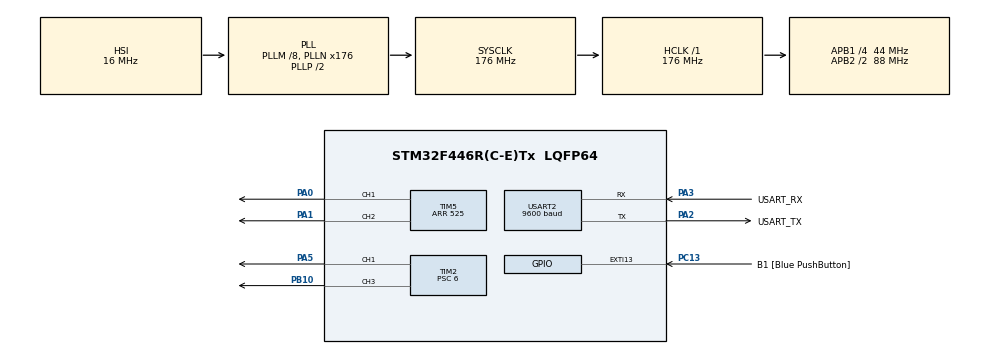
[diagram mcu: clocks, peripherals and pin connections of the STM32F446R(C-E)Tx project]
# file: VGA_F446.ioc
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Mcu.Family=STM32F4
Mcu.Name=STM32F446R(C-E)Tx
Mcu.Package=LQFP64
NVIC.PriorityGroup=NVIC_PRIORITYGROUP_0
NVIC.TIM2_IRQn=true\:0\:0\:false\:false\:true\:true\:true\:true
PA0-WKUP.Signal=S_TIM5_CH1
PA1.Signal=S_TIM5_CH2
PA13.GPIO_Label=TMS
PA13.Mode=Serial_Wire
PA13.Signal=SYS_JTMS-SWDIO
PA14.GPIO_Label=TCK
PA14.Mode=Serial_Wire
PA14.Signal=SYS_JTCK-SWCLK
PA2.GPIO_Label=USART_TX
PA2.Mode=Asynchronous
PA2.Signal=USART2_TX
PA3.GPIO_Label=USART_RX
PA3.Mode=Asynchronous
PA3.Signal=USART2_RX
PA5.Signal=S_TIM2_CH1_ETR
PB10.Signal=S_TIM2_CH3
PB3.GPIO_Label=SWO
PB3.Signal=SYS_JTDO-SWO
PC13.GPIO_Label=B1 [Blue PushButton]
PC13.GPIO_ModeDefaultEXTI=GPIO_MODE_IT_FALLING
PC13.Signal=GPXTI13
PC14-OSC32_IN.Mode=LSE-External-Oscillator
PC14-OSC32_IN.Signal=RCC_OSC32_IN
PC15-OSC32_OUT.Mode=LSE-External-Oscillator
PC15-OSC32_OUT.Signal=RCC_OSC32_OUT
PH0-OSC_IN.Mode=HSE-External-Oscillator
PH0-OSC_IN.Signal=RCC_OSC_IN
PH1-OSC_OUT.Mode=HSE-External-Oscillator
PH1-OSC_OUT.Signal=RCC_OSC_OUT
ProjectManager.HeapSize=0x200
ProjectManager.StackSize=0x400
ProjectManager.TargetToolchain=STM32CubeIDE
RCC.48MHZClocksFreq_Value=84000000
RCC.AHBFreq_Value=176000000
RCC.APB1CLKDivider=RCC_HCLK_DIV4
RCC.APB1Freq_Value=44000000
RCC.APB1TimFreq_Value=88000000
RCC.APB2CLKDivider=RCC_HCLK_DIV2
RCC.APB2Freq_Value=88000000
RCC.APB2TimFreq_Value=176000000
RCC.CortexFreq_Value=176000000
RCC.FLatency-AdvancedSettings=FLASH_LATENCY_5
RCC.HCLKFreq_Value=176000000
RCC.HSE_VALUE=8000000
RCC.HSI_VALUE=16000000
RCC.PLLM=8
RCC.PLLN=176
RCC.SYSCLKFreq_VALUE=176000000
RCC.SYSCLKSource=RCC_SYSCLKSOURCE_PLLCLK
RCC.USBFreq_Value=176000000
RCC.VCOOutputFreq_Value=352000000
SH.S_TIM2_CH1_ETR.0=TIM2_CH1,Output Compare1 CH1
SH.S_TIM2_CH3.0=TIM2_CH3,PWM Generation3 CH3
SH.S_TIM5_CH1.0=TIM5_CH1,PWM Generation1 CH1
SH.S_TIM5_CH2.0=TIM5_CH2,Output Compare2 CH2
TIM2.AutoReloadPreload=TIM_AUTORELOAD_PRELOAD_DISABLE
TIM2.Channel-Output\ Compare1\ CH1=TIM_CHANNEL_1
TIM2.Channel-PWM\ Generation3\ CH3=TIM_CHANNEL_3
TIM2.OCMode_1=TIM_OCMODE_TOGGLE
TIM2.Period=800
TIM2.Prescaler=6
TIM2.Pulse-Output\ Compare1\ CH1=144
TIM2.Pulse-PWM\ Generation3\ CH3=96
TIM2.TIM_MasterOutputTrigger=TIM_TRGO_UPDATE
TIM2.TIM_MasterSlaveMode=TIM_MASTERSLAVEMODE_DISABLE
TIM5.Channel-Output\ Compare2\ CH2=TIM_CHANNEL_2
TIM5.Channel-PWM\ Generation1\ CH1=TIM_CHANNEL_1
TIM5.OCMode_2=TIM_OCMODE_TOGGLE
TIM5.OCPolarity_1=TIM_OCPOLARITY_HIGH
TIM5.Period=525
TIM5.Pulse-Output\ Compare2\ CH2=35
TIM5.Pulse-PWM\ Generation1\ CH1=2
USART2.BaudRate=9600
USART2.VirtualMode=VM_ASYNC
VP_TIM2_VS_ClockSourceINT.Mode=Internal
VP_TIM5_VS_ClockSourceITR.Mode=TriggerSource_ITR0
VP_TIM5_VS_ControllerModeClock.Mode=Clock Mode
board=NUCLEO-F446RE

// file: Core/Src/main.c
/* USER CODE BEGIN Header */
/**
  ******************************************************************************
  * @file           : main.c
  * @brief          : Main program body
  ******************************************************************************
  * @attention
  *
  * Copyright (c) 2024 STMicroelectronics.
  * All rights reserved.
  *
  * This software is licensed under terms that can be found in the LICENSE file
  * in the root directory of this software component.
  * If no LICENSE file comes with this software, it is provided AS-IS.
  *
  ******************************************************************************
  */
/* USER CODE END Header */
#include "main.h"

TIM_HandleTypeDef htim2;
TIM_HandleTypeDef htim5;

UART_HandleTypeDef huart2;

void SystemClock_Config(void);
static void MX_GPIO_Init(void);
static void MX_TIM2_Init(void);
static void MX_TIM5_Init(void);
static void MX_USART2_UART_Init(void);

int main(void)
{

  /* MCU Configuration--------------------------------------------------------*/

  /* Reset of all peripherals, Initializes the Flash interface and the Systick. */
  HAL_Init();

  /* Configure the system clock */
  SystemClock_Config();

  /* Initialize all configured peripherals */
  MX_GPIO_Init();
  MX_TIM2_Init();
  MX_TIM5_Init();
  MX_USART2_UART_Init();
  /* USER CODE BEGIN 2 */

  HAL_TIM_Base_Start(&htim2);
  HAL_TIM_OC_Start(&htim2, TIM_CHANNEL_1);
  HAL_TIM_PWM_Start(&htim2, TIM_CHANNEL_3);
  HAL_TIM_Base_Start(&htim5);
  HAL_TIM_PWM_Start(&htim5, TIM_CHANNEL_1);
  HAL_TIM_OC_Start(&htim5, TIM_CHANNEL_2);

  /* USER CODE END 2 */

  /* Infinite loop */
  while (1)
  {

  }
}

void SystemClock_Config(void)
{
  RCC_OscInitTypeDef RCC_OscInitStruct = {0};
  RCC_ClkInitTypeDef RCC_ClkInitStruct = {0};

  /** Configure the main internal regulator output voltage
  */
  __HAL_RCC_PWR_CLK_ENABLE();
  __HAL_PWR_VOLTAGESCALING_CONFIG(PWR_REGULATOR_VOLTAGE_SCALE1);

  /** Initializes the RCC Oscillators according to the specified parameters
  * in the RCC_OscInitTypeDef structure.
  */
  RCC_OscInitStruct.OscillatorType = RCC_OSCILLATORTYPE_HSI;
  RCC_OscInitStruct.HSIState = RCC_HSI_ON;
  RCC_OscInitStruct.HSICalibrationValue = RCC_HSICALIBRATION_DEFAULT;
  RCC_OscInitStruct.PLL.PLLState = RCC_PLL_ON;
  RCC_OscInitStruct.PLL.PLLSource = RCC_PLLSOURCE_HSI;
  RCC_OscInitStruct.PLL.PLLM = 8;
  RCC_OscInitStruct.PLL.PLLN = 176;
  RCC_OscInitStruct.PLL.PLLP = RCC_PLLP_DIV2;
  RCC_OscInitStruct.PLL.PLLQ = 2;
  RCC_OscInitStruct.PLL.PLLR = 2;
  if (HAL_RCC_OscConfig(&RCC_OscInitStruct) != HAL_OK)
  {
    Error_Handler();
  }

  /** Activate the Over-Drive mode
  */
  if (HAL_PWREx_EnableOverDrive() != HAL_OK)
  {
    Error_Handler();
  }

  /** Initializes the CPU, AHB and APB buses clocks
  */
  RCC_ClkInitStruct.ClockType = RCC_CLOCKTYPE_HCLK|RCC_CLOCKTYPE_SYSCLK
                              |RCC_CLOCKTYPE_PCLK1|RCC_CLOCKTYPE_PCLK2;
  RCC_ClkInitStruct.SYSCLKSource = RCC_SYSCLKSOURCE_PLLCLK;
  RCC_ClkInitStruct.AHBCLKDivider = RCC_SYSCLK_DIV1;
  RCC_ClkInitStruct.APB1CLKDivider = RCC_HCLK_DIV4;
  RCC_ClkInitStruct.APB2CLKDivider = RCC_HCLK_DIV2;

  if (HAL_RCC_ClockConfig(&RCC_ClkInitStruct, FLASH_LATENCY_5) != HAL_OK)
  {
    Error_Handler();
  }
}

static void MX_TIM2_Init(void)
{

  TIM_ClockConfigTypeDef sClockSourceConfig = {0};
  TIM_MasterConfigTypeDef sMasterConfig = {0};
  TIM_OC_InitTypeDef sConfigOC = {0};

  htim2.Instance = TIM2;
  htim2.Init.Prescaler = 6;
  htim2.Init.CounterMode = TIM_COUNTERMODE_UP;
  htim2.Init.Period = 800;
  htim2.Init.ClockDivision = TIM_CLOCKDIVISION_DIV1;
  htim2.Init.AutoReloadPreload = TIM_AUTORELOAD_PRELOAD_DISABLE;
  if (HAL_TIM_Base_Init(&htim2) != HAL_OK)
  {
    Error_Handler();
  }
  sClockSourceConfig.ClockSource = TIM_CLOCKSOURCE_INTERNAL;
  if (HAL_TIM_ConfigClockSource(&htim2, &sClockSourceConfig) != HAL_OK)
  {
    Error_Handler();
  }
  if (HAL_TIM_OC_Init(&htim2) != HAL_OK)
  {
    Error_Handler();
  }
  if (HAL_TIM_PWM_Init(&htim2) != HAL_OK)
  {
    Error_Handler();
  }
  sMasterConfig.MasterOutputTrigger = TIM_TRGO_UPDATE;
  sMasterConfig.MasterSlaveMode = TIM_MASTERSLAVEMODE_DISABLE;
  if (HAL_TIMEx_MasterConfigSynchronization(&htim2, &sMasterConfig) != HAL_OK)
  {
    Error_Handler();
  }
  sConfigOC.OCMode = TIM_OCMODE_TOGGLE;
  sConfigOC.Pulse = 144;
  sConfigOC.OCPolarity = TIM_OCPOLARITY_HIGH;
  sConfigOC.OCFastMode = TIM_OCFAST_DISABLE;
  if (HAL_TIM_OC_ConfigChannel(&htim2, &sConfigOC, TIM_CHANNEL_1) != HAL_OK)
  {
    Error_Handler();
  }
  sConfigOC.OCMode = TIM_OCMODE_PWM1;
  sConfigOC.Pulse = 96;
  if (HAL_TIM_PWM_ConfigChannel(&htim2, &sConfigOC, TIM_CHANNEL_3) != HAL_OK)
  {
    Error_Handler();
  }
  HAL_TIM_MspPostInit(&htim2);

}

static void MX_TIM5_Init(void)
{

  TIM_SlaveConfigTypeDef sSlaveConfig = {0};
  TIM_MasterConfigTypeDef sMasterConfig = {0};
  TIM_OC_InitTypeDef sConfigOC = {0};

  htim5.Instance = TIM5;
  htim5.Init.Prescaler = 0;
  htim5.Init.CounterMode = TIM_COUNTERMODE_UP;
  htim5.Init.Period = 525;
  htim5.Init.ClockDivision = TIM_CLOCKDIVISION_DIV1;
  htim5.Init.AutoReloadPreload = TIM_AUTORELOAD_PRELOAD_DISABLE;
  if (HAL_TIM_Base_Init(&htim5) != HAL_OK)
  {
    Error_Handler();
  }
  if (HAL_TIM_PWM_Init(&htim5) != HAL_OK)
  {
    Error_Handler();
  }
  if (HAL_TIM_OC_Init(&htim5) != HAL_OK)
  {
    Error_Handler();
  }
  sSlaveConfig.SlaveMode = TIM_SLAVEMODE_EXTERNAL1;
  sSlaveConfig.InputTrigger = TIM_TS_ITR0;
  if (HAL_TIM_SlaveConfigSynchro(&htim5, &sSlaveConfig) != HAL_OK)
  {
    Error_Handler();
  }
  sMasterConfig.MasterOutputTrigger = TIM_TRGO_RESET;
  sMasterConfig.MasterSlaveMode = TIM_MASTERSLAVEMODE_DISABLE;
  if (HAL_TIMEx_MasterConfigSynchronization(&htim5, &sMasterConfig) != HAL_OK)
  {
    Error_Handler();
  }
  sConfigOC.OCMode = TIM_OCMODE_PWM1;
  sConfigOC.Pulse = 2;
  sConfigOC.OCPolarity = TIM_OCPOLARITY_HIGH;
  sConfigOC.OCFastMode = TIM_OCFAST_DISABLE;
  if (HAL_TIM_PWM_ConfigChannel(&htim5, &sConfigOC, TIM_CHANNEL_1) != HAL_OK)
  {
    Error_Handler();
  }
  sConfigOC.OCMode = TIM_OCMODE_TOGGLE;
  sConfigOC.Pulse = 35;
  if (HAL_TIM_OC_ConfigChannel(&htim5, &sConfigOC, TIM_CHANNEL_2) != HAL_OK)
  {
    Error_Handler();
  }
  HAL_TIM_MspPostInit(&htim5);

}

static void MX_USART2_UART_Init(void)
{

  huart2.Instance = USART2;
  huart2.Init.BaudRate = 9600;
  huart2.Init.WordLength = UART_WORDLENGTH_8B;
  huart2.Init.StopBits = UART_STOPBITS_1;
  huart2.Init.Parity = UART_PARITY_NONE;
  huart2.Init.Mode = UART_MODE_TX_RX;
  huart2.Init.HwFlowCtl = UART_HWCONTROL_NONE;
  huart2.Init.OverSampling = UART_OVERSAMPLING_16;
  if (HAL_UART_Init(&huart2) != HAL_OK)
  {
    Error_Handler();
  }

}

static void MX_GPIO_Init(void)
{
  GPIO_InitTypeDef GPIO_InitStruct = {0};

  /* GPIO Ports Clock Enable */
  __HAL_RCC_GPIOC_CLK_ENABLE();
  __HAL_RCC_GPIOH_CLK_ENABLE();
  __HAL_RCC_GPIOA_CLK_ENABLE();
  __HAL_RCC_GPIOB_CLK_ENABLE();
  __HAL_RCC_GPIOD_CLK_ENABLE();

  /*Configure GPIO pin : B1_Pin */
  GPIO_InitStruct.Pin = B1_Pin;
  GPIO_InitStruct.Mode = GPIO_MODE_IT_FALLING;
  GPIO_InitStruct.Pull = GPIO_NOPULL;
  HAL_GPIO_Init(B1_GPIO_Port, &GPIO_InitStruct);

  /*Configure GPIO pins : PC0 PC1 PC2 PC3
                           PC4 PC5 PC6 PC7
                           PC8 PC9 PC10 PC11
                           PC12 */
  GPIO_InitStruct.Pin = GPIO_PIN_0|GPIO_PIN_1|GPIO_PIN_2|GPIO_PIN_3
                          |GPIO_PIN_4|GPIO_PIN_5|GPIO_PIN_6|GPIO_PIN_7
                          |GPIO_PIN_8|GPIO_PIN_9|GPIO_PIN_10|GPIO_PIN_11
                          |GPIO_PIN_12;
  GPIO_InitStruct.Mode = GPIO_MODE_ANALOG;
  GPIO_InitStruct.Pull = GPIO_NOPULL;
  HAL_GPIO_Init(GPIOC, &GPIO_InitStruct);

  /*Configure GPIO pins : PA4 PA6 PA7 PA8
                           PA9 PA10 PA11 PA12
                           PA15 */
  GPIO_InitStruct.Pin = GPIO_PIN_4|GPIO_PIN_6|GPIO_PIN_7|GPIO_PIN_8
                          |GPIO_PIN_9|GPIO_PIN_10|GPIO_PIN_11|GPIO_PIN_12
                          |GPIO_PIN_15;
  GPIO_InitStruct.Mode = GPIO_MODE_ANALOG;
  GPIO_InitStruct.Pull = GPIO_NOPULL;
  HAL_GPIO_Init(GPIOA, &GPIO_InitStruct);

  /*Configure GPIO pins : PB0 PB1 PB2 PB12
                           PB13 PB14 PB15 PB4
                           PB5 PB6 PB7 PB8
                           PB9 */
  GPIO_InitStruct.Pin = GPIO_PIN_0|GPIO_PIN_1|GPIO_PIN_2|GPIO_PIN_12
                          |GPIO_PIN_13|GPIO_PIN_14|GPIO_PIN_15|GPIO_PIN_4
                          |GPIO_PIN_5|GPIO_PIN_6|GPIO_PIN_7|GPIO_PIN_8
                          |GPIO_PIN_9;
  GPIO_InitStruct.Mode = GPIO_MODE_ANALOG;
  GPIO_InitStruct.Pull = GPIO_NOPULL;
  HAL_GPIO_Init(GPIOB, &GPIO_InitStruct);

  /*Configure GPIO pin : PD2 */
  GPIO_InitStruct.Pin = GPIO_PIN_2;
  GPIO_InitStruct.Mode = GPIO_MODE_ANALOG;
  GPIO_InitStruct.Pull = GPIO_NOPULL;
  HAL_GPIO_Init(GPIOD, &GPIO_InitStruct);

}

void Error_Handler(void)
{
  __disable_irq();
  while (1)
  {
  }
}
